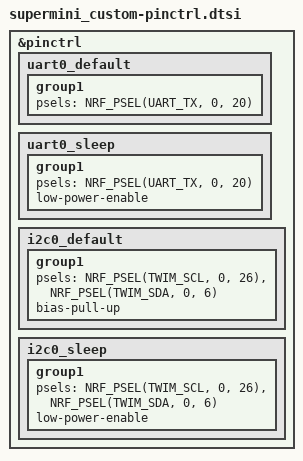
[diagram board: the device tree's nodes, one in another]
#include <zephyr/dt-bindings/pinctrl/nrf-pinctrl.h>

&pinctrl {
	uart0_default: uart0_default {
		group1 {
			psels = <NRF_PSEL(UART_TX, 0, 20)>;
		};
	};

	uart0_sleep: uart0_sleep {
		group1 {
			psels = <NRF_PSEL(UART_TX, 0, 20)>;
			low-power-enable;
		};
	};

	i2c0_default: i2c0_default {
		group1 {
			psels = <NRF_PSEL(TWIM_SCL, 0, 26)>,
				<NRF_PSEL(TWIM_SDA, 0, 6)>;
			bias-pull-up;
		};
	};

	i2c0_sleep: i2c0_sleep {
		group1 {
			psels = <NRF_PSEL(TWIM_SCL, 0, 26)>,
				<NRF_PSEL(TWIM_SDA, 0, 6)>;
			low-power-enable;
		};
	};
};
